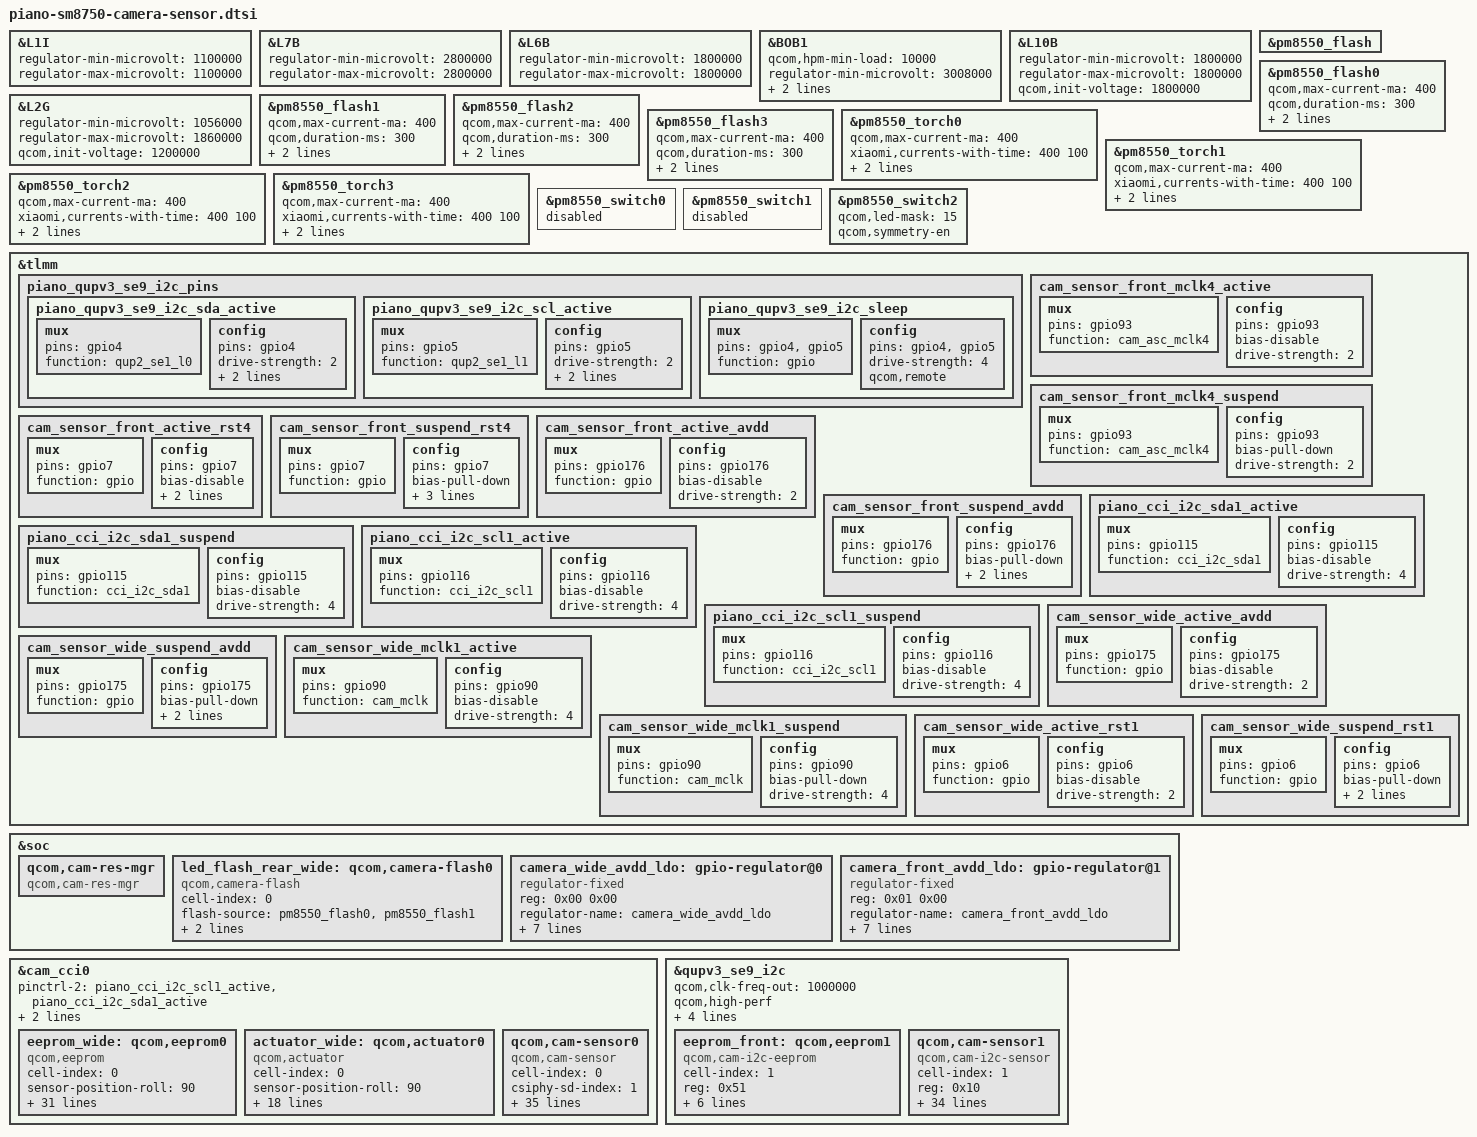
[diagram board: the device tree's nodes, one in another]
#include <dt-bindings/msm-camera.h>


&L1I {
	regulator-min-microvolt = <1100000>;
	regulator-max-microvolt = <1100000>;
};

&L7B {
	regulator-min-microvolt = <2800000>;
	regulator-max-microvolt = <2800000>;
};

&L6B{
	regulator-min-microvolt = <1800000>;
	regulator-max-microvolt = <1800000>;
};

&BOB1{
	qcom,hpm-min-load = <10000>;        
	regulator-min-microvolt = <3008000>;
	regulator-max-microvolt = <3960000>;
	qcom,init-voltage = <3328000>;
};

&L10B {
	regulator-min-microvolt = <1800000>;
	regulator-max-microvolt = <1800000>;
	qcom,init-voltage = <1800000>;
};

&L2G {
	regulator-min-microvolt = <1056000>;
	regulator-max-microvolt = <1860000>;
	qcom,init-voltage = <1200000>;
};

&pm8550_flash {
	status = "ok";
};

&pm8550_flash0 {
	qcom,max-current-ma = <400>;
	qcom,duration-ms = <300>;
	xiaomi,max-duration-ms = <300>;
	qcom,ires-ua = <5000>;
};

&pm8550_flash1 {
        qcom,max-current-ma = <400>;
        qcom,duration-ms = <300>;
        xiaomi,max-duration-ms = <300>;
        qcom,ires-ua = <5000>;
};

&pm8550_flash2 {
        qcom,max-current-ma = <400>;
        qcom,duration-ms = <300>;
        xiaomi,max-duration-ms = <300>;
        qcom,ires-ua = <5000>;
};

&pm8550_flash3 {
        qcom,max-current-ma = <400>;
        qcom,duration-ms = <300>;
        xiaomi,max-duration-ms = <300>;
        qcom,ires-ua = <5000>;
};

&pm8550_torch0{
	qcom,max-current-ma = <400>;
	xiaomi,currents-with-time = <400 100>;
	xiaomi,time-for-currents = <5000 0xFFFFFFFF>;  /* 0xFFFFFFFF means flash always on*/
	qcom,ires-ua = <5000>;
};

&pm8550_torch1{
	qcom,max-current-ma = <400>;
	xiaomi,currents-with-time = <400 100>;
	xiaomi,time-for-currents = <5000 0xFFFFFFFF>;  /* 0xFFFFFFFF means flash always on*/
	qcom,ires-ua = <5000>;
};

&pm8550_torch2{
	qcom,max-current-ma = <400>;
	xiaomi,currents-with-time = <400 100>;
	xiaomi,time-for-currents = <5000 0xFFFFFFFF>;  /* 0xFFFFFFFF means flash always on*/
	qcom,ires-ua = <5000>;
};

&pm8550_torch3{
        qcom,max-current-ma = <400>;
        xiaomi,currents-with-time = <400 100>;
        xiaomi,time-for-currents = <5000 0xFFFFFFFF>;  /* 0xFFFFFFFF means flash always on*/
        qcom,ires-ua = <5000>;
};

&pm8550_switch0 {
	status = "disabled";
};

&pm8550_switch1 {
	status = "disabled";
};

&pm8550_switch2 {
	qcom,led-mask = <15>; // Channels All
	qcom,symmetry-en;
};

&tlmm {
	piano_qupv3_se9_i2c_pins: piano_qupv3_se9_i2c_pins {
		piano_qupv3_se9_i2c_sda_active: piano_qupv3_se9_i2c_sda_active {
			mux {
				pins = "gpio4";
				function = "qup2_se1_l0";
			};

			config {
				pins = "gpio4";
				drive-strength = <2>;
				bias-disable; /* NO PULL */
				qcom,apps;
			};
		};

		piano_qupv3_se9_i2c_scl_active: piano_qupv3_se9_i2c_scl_active {
			mux {
				pins = "gpio5";
				function = "qup2_se1_l1";
			};

			config {
				pins = "gpio5";
				drive-strength = <2>;
				bias-disable; /* NO PULL */
				qcom,apps;
			};
		};

		piano_qupv3_se9_i2c_sleep: piano_qupv3_se9_i2c_sleep {
			mux {
				pins = "gpio4", "gpio5";
				function = "gpio";
			};

			config {
				pins = "gpio4", "gpio5";
				drive-strength = <4>;
				qcom,remote;
			};
		};
	};

	cam_sensor_front_mclk4_active: cam_sensor_front_mclk4_active {
		/* MCLK4 */
		mux {
			pins = "gpio93";
			function = "cam_asc_mclk4";
		};

		config {
			pins = "gpio93";
			bias-disable; /* No PULL */
			drive-strength = <2>; /* 2 MA */
		};
	};

	cam_sensor_front_mclk4_suspend: cam_sensor_front_mclk4_suspend {
		/* MCLK4 */
		mux {
			pins = "gpio93";
			function = "cam_asc_mclk4";
		};

		config {
			pins = "gpio93";
			bias-pull-down; /* PULL DOWN */
			drive-strength = <2>; /* 2 MA */
		};
	};

	cam_sensor_front_active_rst4: cam_sensor_front_active_rst4 {
		mux {
			pins = "gpio7";
			function = "gpio";
		};

		config {
			pins = "gpio7";
			bias-disable; /* No PULL */
			drive-strength = <2>; /* 2 MA */
			qcom,apps;
		};
	};

	cam_sensor_front_suspend_rst4: cam_sensor_front_suspend_rst4 {
		mux {
			pins = "gpio7";
			function = "gpio";
		};

		config {
			pins = "gpio7";
			bias-pull-down; /* PULL DOWN */
			drive-strength = <2>; /* 2 MA */
			output-low;
			qcom,remote;
		};
	};

	cam_sensor_front_active_avdd: cam_sensor_front_active_avdd {
		mux {
			pins = "gpio176";
			function = "gpio";
		};

		config {
			pins = "gpio176";
			bias-disable; /* No PULL */
			drive-strength = <2>; /* 2 MA */
		};
	};

	cam_sensor_front_suspend_avdd: cam_sensor_front_suspend_avdd {
		mux {
			pins = "gpio176";
			function = "gpio";
		};

		config {
			pins = "gpio176";
			bias-pull-down; /* PULL DOWN */
			drive-strength = <2>; /* 2 MA */
			output-low;
		};
	};

	piano_cci_i2c_sda1_active: piano_cci_i2c_sda1_active {
		mux {
			/* CLK, DATA */
			pins = "gpio115";
			function = "cci_i2c_sda1";
		};

		config {
			pins = "gpio115";
			bias-disable; /* No PULL */
			drive-strength = <4>; /* 4 MA */
		};
	};

	piano_cci_i2c_sda1_suspend: piano_cci_i2c_sda1_suspend {
		mux {
			/* CLK, DATA */
			pins = "gpio115";
			function = "cci_i2c_sda1";
		};

		config {
			pins = "gpio115";
			bias-disable; /* No DOWN */
			drive-strength = <4>; /* 4 MA */
		};
	};

	piano_cci_i2c_scl1_active: piano_cci_i2c_scl1_active {
		mux {
			/* CLK, DATA */
			pins = "gpio116";
			function = "cci_i2c_scl1";
		};

		config {
			pins = "gpio116";
			bias-disable; /* No PULL */
			drive-strength = <4>; /* 4 MA */
		};
	};

	piano_cci_i2c_scl1_suspend: piano_cci_i2c_scl1_suspend {
		mux {
			/* CLK, DATA */
			pins = "gpio116";
			function = "cci_i2c_scl1";
		};

		config {
			pins = "gpio116";
			bias-disable; /* No DOWN */
			drive-strength = <4>; /* 4 MA */
		};
	};

	cam_sensor_wide_active_avdd: cam_sensor_wide_active_avdd {
        mux {
            pins = "gpio175";
            function = "gpio";
        };
        config {
            pins = "gpio175";
            bias-disable; /* No PULL */
            drive-strength = <2>; /* 2 MA */
        };
    };

    cam_sensor_wide_suspend_avdd: cam_sensor_wide_suspend_avdd {
        mux {
            pins = "gpio175";
            function = "gpio";
        };
        config {
            pins = "gpio175";
            bias-pull-down; /* PULL DOWN */
            drive-strength = <2>; /* 2 MA */
            output-low;
        };
    };

    cam_sensor_wide_mclk1_active: cam_sensor_wide_mclk1_active {
        mux {
            pins = "gpio90";
            function = "cam_mclk";
        };
        config {
            pins = "gpio90";
            bias-disable; /* No PULL */
            drive-strength = <4>; /* 4 MA */
        };
    };

    cam_sensor_wide_mclk1_suspend: cam_sensor_wide_mclk1_suspend {
        mux {
            pins = "gpio90";
            function = "cam_mclk";
        };
        config {
            pins = "gpio90";
            bias-pull-down; /* PULL DOWN */
            drive-strength = <4>; /* 4 MA */
        };
    };

    cam_sensor_wide_active_rst1: cam_sensor_wide_active_rst1 {
        mux {
            pins = "gpio6";
            function = "gpio";
        };
        config {
            pins = "gpio6";
            bias-disable; /* No PULL */
            drive-strength = <2>; /* 2 MA */
        };
    };

    cam_sensor_wide_suspend_rst1: cam_sensor_wide_suspend_rst1 {
        mux {
            pins = "gpio6";
            function = "gpio";
        };
        config {
            pins = "gpio6";
            bias-pull-down; /* PULL DOWN */
            drive-strength = <2>; /* 2 MA */
            output-low;
        };
    };
};


&soc {
    qcom,cam-res-mgr {
		compatible = "qcom,cam-res-mgr";
		status = "ok";
    };

    led_flash_rear_wide: qcom,camera-flash0 {
		cell-index = <0>;
		compatible = "qcom,camera-flash";
		flash-source = <&pm8550_flash0 &pm8550_flash1>;
		torch-source = <&pm8550_torch0 &pm8550_torch1>;
		switch-source = <&pm8550_switch2>;
		status = "ok";
    };

	camera_wide_avdd_ldo: gpio-regulator@0 {
		compatible = "regulator-fixed";
		reg = <0x00 0x00>;
		regulator-name = "camera_wide_avdd_ldo";
		regulator-min-microvolt = <2800000>;
		regulator-max-microvolt = <2800000>;
		regulator-enable-ramp-delay = <100>;
		enable-active-high;
		gpio = <&tlmm 175 0>;
		pinctrl-names = "wide_avdd_active", "wide_avdd_suspend";
		pinctrl-0 = <&cam_sensor_wide_active_avdd
				&cam_sensor_wide_suspend_avdd>;
    };

	camera_front_avdd_ldo: gpio-regulator@1 {
		compatible = "regulator-fixed";
		reg = <0x01 0x00>;
		regulator-name = "camera_front_avdd_ldo";
		regulator-min-microvolt = <2800000>;
		regulator-max-microvolt = <2800000>;
		regulator-enable-ramp-delay = <100>;
		enable-active-high;
		gpio = <&tlmm 176 0>;
		pinctrl-names = "front_avdd_active", "front_avdd_suspend";
		pinctrl-0 = <&cam_sensor_front_active_avdd
				&cam_sensor_front_suspend_avdd>;
    };
};

&cam_cci0 {
	pinctrl-2 = <&piano_cci_i2c_scl1_active &piano_cci_i2c_sda1_active>;
	pinctrl-3 = <&piano_cci_i2c_scl1_suspend &piano_cci_i2c_sda1_suspend>;
	eeprom_wide: qcom,eeprom0 {
		cell-index = <0>;
		compatible = "qcom,eeprom";
		sensor-position-roll = <90>;
		sensor-position-pitch = <0>;
		sensor-position-yaw = <180>;
		cam_vana-supply = <&camera_wide_avdd_ldo>;
		cam_vio-supply = <&L6B>;
		cam_vdig-supply = <&L1I>;
		cam_clk-supply = <&cam_cc_titan_top_gdsc>;
		cam_bob-supply = <&BOB1>;
		regulator-names = "cam_vana", "cam_vio", "cam_vdig", "cam_clk", "cam_bob";
		rgltr-cntrl-support;
		rgltr-min-voltage = <2800000  1800000 1100000  0  3008000>;
		rgltr-max-voltage = <2800000  1800000 1100000  0  3960000>;
		rgltr-load-current = <160000   50000  750000  0 1000000>;
		gpio-no-mux = <0>;
		pinctrl-names = "cam_default", "cam_suspend";
		pinctrl-0 = <&cam_sensor_wide_mclk1_active
		        &cam_sensor_wide_active_rst1>;
		pinctrl-1 = <&cam_sensor_wide_mclk1_suspend
		        &cam_sensor_wide_suspend_rst1>;
		gpios = <&tlmm 90 0>, <&tlmm 6 0>;
		gpio-reset = <1>;
		gpio-req-tbl-num = <0 1>;
		gpio-req-tbl-flags = <1 0>;
		gpio-req-tbl-label = "CAMIF_MCLK1", "CAM_RESET1";
		cci-master = <CCI_MASTER_1>;
		clocks = <&cambistmclkcc CAM_BIST_MCLK_CC_MCLK1_CLK>;
		clock-names = "cam_clk";
		clock-cntl-level = "nominal";
		clock-rates = <19200000>;
		status = "ok";
	};

	// wide actuator
	actuator_wide: qcom,actuator0 {
		cell-index = <0>;
		compatible = "qcom,actuator";
		sensor-position-roll = <90>;
		sensor-position-pitch = <0>;
		sensor-position-yaw = <180>;
		cam_vana-supply = <&camera_wide_avdd_ldo>;
		cam_vio-supply = <&L6B>;
		cam_vdig-supply = <&L1I>;
		cam_clk-supply = <&cam_cc_titan_top_gdsc>;
		cam_vaf-supply = <&L7B>;
		cam_bob-supply = <&BOB1>;
		regulator-names = "cam_vana", "cam_vio", "cam_vdig", "cam_clk", "cam_vaf", "cam_bob";
		rgltr-cntrl-support;
		rgltr-min-voltage = <2800000  1800000 1100000  0 2800000 3008000>;
		rgltr-max-voltage = <2800000  1800000 1100000  0 2800000 3960000>;
		rgltr-load-current = <160000   50000  750000  0 130000 1000000>;
		cci-master = <CCI_MASTER_1>;
		status = "ok";
	};

	// wide sensor
    qcom,cam-sensor0 {
        cell-index = <0>;
        compatible = "qcom,cam-sensor";
        csiphy-sd-index = <1>;
        actuator-src = <&actuator_wide>;
        eeprom-src = <&eeprom_wide>;
        led-flash-src = <&led_flash_rear_wide>;
        sensor-position-roll = <90>;
        sensor-position-pitch = <0>;
        sensor-position-yaw = <180>;
        cam_vana-supply = <&camera_wide_avdd_ldo>;
        cam_vio-supply = <&L6B>;
        cam_vdig-supply = <&L1I>;
        cam_clk-supply = <&cam_cc_titan_top_gdsc>;
		cam_bob-supply = <&BOB1>;
        regulator-names = "cam_vana", "cam_vio", "cam_vdig", "cam_clk", "cam_bob";
        rgltr-cntrl-support;
        rgltr-min-voltage = <2800000  1800000 1100000  0  3008000>;
        rgltr-max-voltage = <2800000  1800000 1100000  0  3960000>;
        rgltr-load-current = <160000   50000  750000  0 1000000>;
        //use-shared-clk;
        gpio-no-mux = <0>;
        pinctrl-names = "cam_default", "cam_suspend";
        pinctrl-0 = <&cam_sensor_wide_mclk1_active
                &cam_sensor_wide_active_rst1>;
        pinctrl-1 = <&cam_sensor_wide_mclk1_suspend
                &cam_sensor_wide_suspend_rst1>;
        gpios = <&tlmm 90 0>, <&tlmm 6 0>;
        gpio-reset = <1>;
        gpio-req-tbl-num = <0 1>;
        gpio-req-tbl-flags = <1 0>;
        gpio-req-tbl-label = "CAMIF_MCLK1", "CAM_RESET1";
        cci-master = <CCI_MASTER_1>;
        clocks = <&cambistmclkcc CAM_BIST_MCLK_CC_MCLK1_CLK>;
        clock-names = "cam_clk";
        clock-cntl-level = "nominal";
        clock-rates = <19200000>;
        status = "ok";
    };
};

&qupv3_se9_i2c {
	status = "ok";
	qcom,clk-freq-out = <1000000>;
	qcom,high-perf;
	qcom,pm-ctrl-client;
	pinctrl-0 = <&piano_qupv3_se9_i2c_sda_active>, <&piano_qupv3_se9_i2c_scl_active>;
	pinctrl-1 = <&piano_qupv3_se9_i2c_sleep>;

	//front
	eeprom_front: qcom,eeprom1 {
		cell-index = <1>;
		reg = <0x51>;
		compatible = "qcom,cam-i2c-eeprom";
		cam_vio-supply = <&L10B>;
		regulator-names = "cam_vio";
		rgltr-cntrl-support;
		rgltr-min-voltage = <1800000>;
		rgltr-max-voltage = <1800000>;
		rgltr-load-current = <150000>;
		status = "ok";
	};

	// Front Sensor
	qcom,cam-sensor1 {
		cell-index = <1>;
		reg = <0x10>;
		compatible = "qcom,cam-i2c-sensor";
		csiphy-sd-index = <4>;
		eeprom-src = <&eeprom_front>;
		sensor-position-roll = <270>;
		sensor-position-pitch = <0>;
		sensor-position-yaw = <0>;
		cam_vana-supply = <&camera_front_avdd_ldo>;
		cam_vio-supply = <&L10B>;
		cam_vdig-supply = <&L2G>;
		cam_clk-supply = <&cam_cc_titan_top_gdsc>;
		cam_bob-supply = <&BOB1>;
		regulator-names = "cam_vana", "cam_vio",
			"cam_vdig", "cam_clk", "cam_bob";
		rgltr-cntrl-support;
		aon-camera-id = <AON_CAM1>;
		rgltr-min-voltage = <2800000 1800000 1200000 0 3008000>;
		rgltr-max-voltage = <2800000 1800000 1200000 0 4000000>;
		rgltr-load-current = <150000 150000 150000 0 2000000>;
		gpio-no-mux = <0>;
		pinctrl-names = "cam_default", "cam_suspend";
		pinctrl-0 = <&cam_sensor_front_mclk4_active
			&cam_sensor_front_active_rst4>;
		pinctrl-1 = <&cam_sensor_front_mclk4_suspend
			&cam_sensor_front_suspend_rst4>;
		gpios = <&tlmm 93 0>, <&tlmm 7 0>;
		gpio-reset = <1>;
		gpio-req-tbl-num = <0 1>;
		gpio-req-tbl-flags = <1 0>;
		gpio-req-tbl-label = "CAMIF_MCLK4", "CAM_RESET4";
		clocks = <&cambistmclkcc CAM_BIST_MCLK_CC_MCLK4_CLK>;
		clock-names = "cam_clk";
		clock-cntl-level = "nominal";
		clock-rates = <19200000>;
		status = "ok";
	};
};
